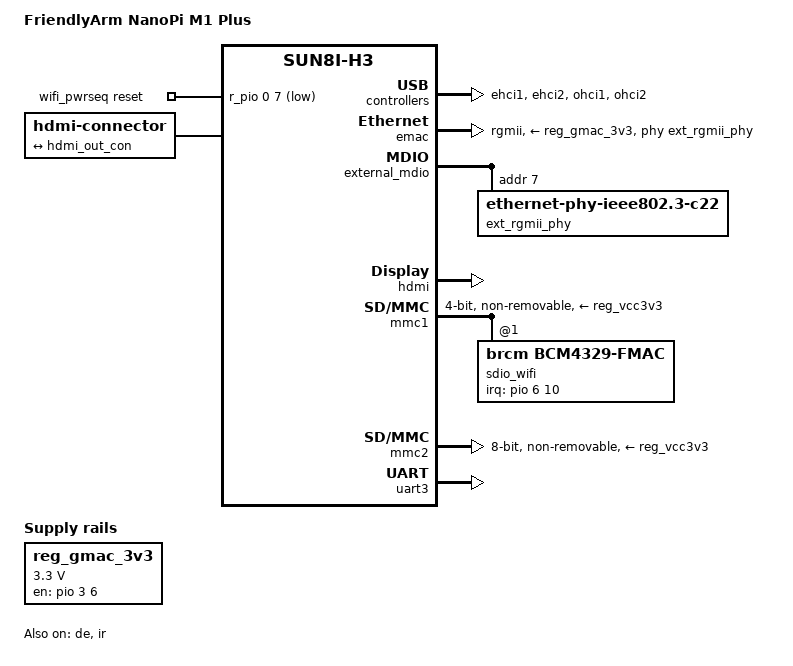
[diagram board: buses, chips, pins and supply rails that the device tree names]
#include "sun8i-h3-nanopi.dtsi"
/ {
	model = "FriendlyArm NanoPi M1 Plus";
	compatible = "friendlyarm,nanopi-m1-plus", "allwinner,sun8i-h3";
	aliases {
		serial1 = &uart3;
		ethernet0 = &emac;
		ethernet1 = &sdio_wifi;
	};
	reg_gmac_3v3: gmac-3v3 {
		compatible = "regulator-fixed";
		regulator-name = "gmac-3v3";
		regulator-min-microvolt = <3300000>;
		regulator-max-microvolt = <3300000>;
		startup-delay-us = <100000>;
		enable-active-high;
		gpio = <&pio 3 6 GPIO_ACTIVE_HIGH>;
	};
	wifi_pwrseq: wifi_pwrseq {
		compatible = "mmc-pwrseq-simple";
		reset-gpios = <&r_pio 0 7 GPIO_ACTIVE_LOW>;  
	};
	connector {
		compatible = "hdmi-connector";
		type = "a";
		port {
			hdmi_con_in: endpoint {
				remote-endpoint = <&hdmi_out_con>;
			};
		};
	};
};
&de {
	status = "okay";
};
&ehci1 {
	status = "okay";
};
&ehci2 {
	status = "okay";
};
&emac {
	pinctrl-names = "default";
	pinctrl-0 = <&emac_rgmii_pins>;
	phy-supply = <&reg_gmac_3v3>;
	phy-handle = <&ext_rgmii_phy>;
	phy-mode = "rgmii";
	status = "okay";
};
&external_mdio {
	ext_rgmii_phy: ethernet-phy@1 {
		compatible = "ethernet-phy-ieee802.3-c22";
		reg = <7>;
	};
};
&hdmi {
	status = "okay";
};
&hdmi_out {
	hdmi_out_con: endpoint {
		remote-endpoint = <&hdmi_con_in>;
	};
};
&ir {
	pinctrl-names = "default";
	pinctrl-0 = <&r_ir_rx_pin>;
	status = "okay";
};
&mmc1 {
	vmmc-supply = <&reg_vcc3v3>;
	vqmmc-supply = <&reg_vcc3v3>;
	mmc-pwrseq = <&wifi_pwrseq>;
	bus-width = <4>;
	non-removable;
	status = "okay";
	sdio_wifi: sdio_wifi@1 {
		reg = <1>;
		compatible = "brcm,bcm4329-fmac";
		interrupt-parent = <&pio>;
		interrupts = <6 10 IRQ_TYPE_LEVEL_LOW>;  
		interrupt-names = "host-wake";
	};
};
&mmc2 {
	pinctrl-names = "default";
	pinctrl-0 = <&mmc2_8bit_pins>;
	vmmc-supply = <&reg_vcc3v3>;
	vqmmc-supply = <&reg_vcc3v3>;
	bus-width = <8>;
	non-removable;
	status = "okay";
};
&ohci1 {
	status = "okay";
};
&ohci2 {
	status = "okay";
};
&uart3 {
	pinctrl-names = "default";
	pinctrl-0 = <&uart3_pins>, <&uart3_rts_cts_pins>;
	status = "okay";
};
